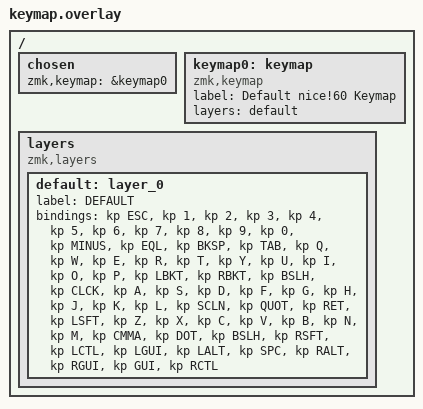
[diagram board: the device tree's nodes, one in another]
#include <behaviors.dtsi>
#include <dt-bindings/zmk/keys.h>
#include <dt-bindings/zmk/matrix-transform.h>

/ {
	chosen {
		zmk,keymap = &keymap0;
	};
	
	keymap0: keymap {
		compatible = "zmk,keymap";
		label ="Default nice!60 Keymap";
		layers = <&default>;
	};

	layers {
		compatible = "zmk,layers";

		default: layer_0 {
			label = "DEFAULT";
// ------------------------------------------------------------------------------------------
// | ESC |  1  |  2  |  3  |  4  |  5  |  6  |  7  |  8  |  9  |  0  |  -  |  =  |   BKSP   |
// | TAB  |  Q  |  W  |  E  |  R  |  T  |  Y  |  U  |  I  |  O  |  P  |  [  |  ]  |   "|"   |
// | CAPS  |  A  |  S  |  D  |  F  |  G  |  H  |  J  |  K  |  L  |  ;  |  '  |     ENTER    |
// |  SHIFT  |  Z  |  X  |  C  |  V  |  B  |  N  |  M  |  ,  |  .  |  /  |      SHIFT       |
// |  CTL  |  WIN  |  ALT  |            SPACE              |  ALT  |  WIN  |  MENU  |  CTL  |
// ------------------------------------------------------------------------------------------
			bindings = <
	&kp ESC &kp 1 &kp 2 &kp 3 &kp 4 &kp 5 &kp 6 &kp 7 &kp 8 &kp 9 &kp 0 &kp MINUS &kp EQL  &kp BKSP
	&kp TAB  &kp Q &kp W &kp E &kp R &kp T &kp Y &kp U &kp I &kp O &kp P &kp LBKT &kp RBKT &kp BSLH
	&kp CLCK  &kp A &kp S &kp D &kp F &kp G &kp H &kp J &kp K &kp L &kp SCLN &kp QUOT       &kp RET
	&kp LSFT   &kp Z &kp X &kp C &kp V &kp B &kp N &kp M &kp CMMA &kp DOT &kp BSLH         &kp RSFT
	&kp LCTL &kp LGUI &kp LALT              &kp SPC            &kp RALT  &kp RGUI  &kp GUI &kp RCTL
			>;
		};
	};
};
